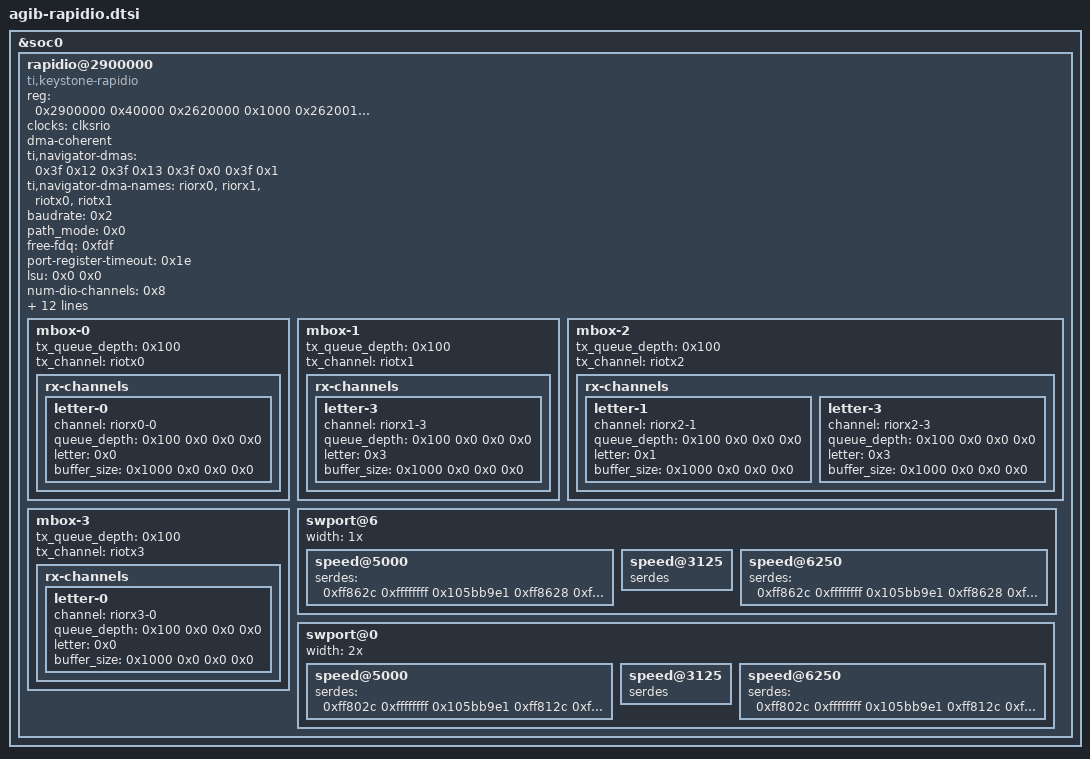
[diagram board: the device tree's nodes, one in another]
&soc0 {
	rapidio@2900000 {
		interrupt-names = "rio", "lsu", "rio-starvation";
		compatible = "ti,keystone-rapidio";
		#address-cells = <0x1>;
		#size-cells = <0x1>;
		reg = <0x2900000 0x40000 0x2620000 0x1000 0x2620018 0x4 0x232c000 0x2000>;
		reg-names = "rio", "boot_config", "jtagid", "serdes";
		clocks = <&clksrio>;
		clock-names = "clk_srio";
		dma-coherent;
		ti,navigator-dmas = <0x3f 0x12 0x3f 0x13 0x3f 0x0 0x3f 0x1>;
		ti,navigator-dma-names = "riorx0", "riorx1", "riotx0", "riotx1";
		baudrate = <0x2>;
		path_mode = <0x0>;
		free-fdq = <0xfdf>;
		port-register-timeout = <0x1e>;
		lsu = <0x0 0x0>;
		num-dio-channels = <0x8>;
		ports = <0x1>;
		ports_remote = <0xe 0x0 0x0 0x0>;
		dev-id-size = <0x1>;
		interrupts = <0x0 0x98 0xf01 0x0 0x99 0xf01 0x0 0xb0 0xf01>;
		tx-bin-queues = <0xfd9 0xfda 0xfdb 0xfdc 0xfdd 0xfde>;
		tx-garbage-queues = <0x2060 0x2060 0x2060 0x2060 0x2060 0x2060>;
		rxu_map_range = <0x2a 0x3f>;

		keystone2-serdes;

		num-mboxes = <0x4>;

		mbox-0 {
			tx_queue_depth = <0x100>;
			tx_channel = "riotx0";

			rx-channels {
				letter-0 {
					channel = "riorx0-0";
					queue_depth = <0x100 0x0 0x0 0x0>;
					letter = <0x0>;
					buffer_size = <0x1000 0x0 0x0 0x0>;
				};
			};
		};

		mbox-1 {
			tx_queue_depth = <0x100>;
			tx_channel = "riotx1";

			rx-channels {
				letter-3 {
					channel = "riorx1-3";
					queue_depth = <0x100 0x0 0x0 0x0>;
					letter = <0x3>;
					buffer_size = <0x1000 0x0 0x0 0x0>;
				};
			};
		};

		mbox-2 {
			tx_queue_depth = <0x100>;
			tx_channel = "riotx2";

			rx-channels {
				letter-1 {
					channel = "riorx2-1";
					queue_depth = <0x100 0x0 0x0 0x0>;
					letter = <0x1>;
					buffer_size = <0x1000 0x0 0x0 0x0>;
				};

				letter-3 {
					channel = "riorx2-3";
					queue_depth = <0x100 0x0 0x0 0x0>;
					letter = <0x3>;
					buffer_size = <0x1000 0x0 0x0 0x0>;
				};
			};
		};

		mbox-3 {
			tx_queue_depth = <0x100>;
			tx_channel = "riotx3";

			rx-channels {
				letter-0 {
					channel = "riorx3-0";
					queue_depth = <0x100 0x0 0x0 0x0>;
					letter = <0x0>;
					buffer_size = <0x1000 0x0 0x0 0x0>;
				};
			};
		};

		swport@6 {
			width = "1x";

			speed@5000 {
				serdes = <0xff862c 0xffffffff 0x105bb9e1 0xff8628 0xffffffff 0x3f555 0x20dc 0x20000000 0x20000020 0xff8600 0x7e0 0x740 0x20dc 0x20000000 0x0>;
			};

			speed@3125 {
				serdes;
			};

			speed@6250 {
				serdes = <0xff862c 0xffffffff 0x105bb9e1 0xff8628 0xffffffff 0x3f555 0x20dc 0x20000000 0x20000020 0xff8600 0x7e0 0x740 0x20dc 0x20000000 0x0>;
			};
		};

		swport@0 {
			width = "2x";

			speed@5000 {
				serdes = <0xff802c 0xffffffff 0x105bb9e1 0xff812c 0xffffffff 0x105bb9e1 0xff822c 0xffffffff 0x105bb9e1 0xff832c 0xffffffff 0x105bb9e1 0xff8028 0xffffffff 0x3f555 0xff8128 0xffffffff 0x3f555 0xff8228 0xffffffff 0x3f555 0xff8328 0xffffffff 0x3f555 0x201c 0x20000000 0x20000000 0x203c 0x20000000 0x20000000 0x205c 0x20000000 0x20000000 0x207c 0x20000000 0x20000000 0xff8000 0x7e0 0x680 0xff8100 0x7e0 0x680 0xff8200 0x7e0 0x680 0xff8300 0x7e0 0x680 0x201c 0x20000000 0x0 0x203c 0x20000000 0x0 0x205c 0x20000000 0x0 0x207c 0x20000000 0x0>;
			};

			speed@3125 {
				serdes;
			};

			speed@6250 {
				serdes = <0xff802c 0xffffffff 0x105bb9e1 0xff812c 0xffffffff 0x105bb9e1 0xff822c 0xffffffff 0x105bb9e1 0xff832c 0xffffffff 0x105bb9e1 0xff8028 0xffffffff 0x3f555 0xff8128 0xffffffff 0x3f555 0xff8228 0xffffffff 0x3f555 0xff8328 0xffffffff 0x3f555 0x201c 0x20000000 0x20000000 0x203c 0x20000000 0x20000000 0x205c 0x20000000 0x20000000 0x207c 0x20000000 0x20000000 0xff8000 0x7e0 0x680 0xff8100 0x7e0 0x680 0xff8200 0x7e0 0x680 0xff8300 0x7e0 0x680 0x201c 0x20000000 0x0 0x203c 0x20000000 0x0 0x205c 0x20000000 0x0 0x207c 0x20000000 0x0>;
			};
		};
	};
};
